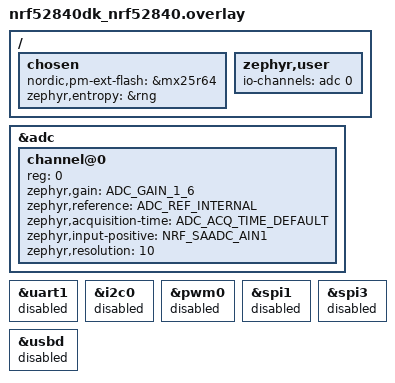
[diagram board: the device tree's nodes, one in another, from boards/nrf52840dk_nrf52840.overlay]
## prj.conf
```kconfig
#
# Copyright (c) 2021 Nordic Semiconductor ASA
#
# SPDX-License-Identifier: LicenseRef-Nordic-5-Clause
#

# This sample uses Kconfig.defaults to set options common for all
# samples. This file should contain only options specific for this sample
# or overrides of default values.

# Enable CHIP
CONFIG_CHIP=y
CONFIG_CHIP_ENABLE_PAIRING_AUTOSTART=y
CONFIG_CHIP_PROJECT_CONFIG="src/chip_project_config.h"
# 32768 == 0x8000 (example Product ID added temporaly,
# but it must be changed with proper PID from the list:
# https://github.com/project-chip/connectedhomeip/blob/482e6fd03196a6de45465a90003947ef4b86e0b1/docs/examples/discussion/PID_allocation_for_example_apps.md)
CONFIG_CHIP_DEVICE_PRODUCT_ID=32768
CONFIG_STD_CPP14=y

# Add support for LEDs and buttons on Nordic development kits
CONFIG_DK_LIBRARY=y

# Bluetooth Low Energy configuration
CONFIG_BT_DEVICE_NAME="MatterTemplate"

# Other settings
CONFIG_THREAD_NAME=y
CONFIG_MPU_STACK_GUARD=y
CONFIG_RESET_ON_FATAL_ERROR=n
CONFIG_CHIP_LIB_SHELL=y

# Disable NFC commissioning
CONFIG_CHIP_NFC_COMMISSIONING=n

# Reduce application size
CONFIG_USE_SEGGER_RTT=n

CONFIG_ADC=y
```

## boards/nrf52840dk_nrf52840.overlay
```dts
/* Copyright (c) 2021 Nordic Semiconductor ASA
 *
 * SPDX-License-Identifier: LicenseRef-Nordic-5-Clause
 */

/ {
	chosen {
		nordic,pm-ext-flash = &mx25r64;
	};
};


/ {
	/*
	* In some default configurations within the nRF Connect SDK,
	* e.g. on nRF52840, the chosen zephyr,entropy node is &cryptocell.
	* This devicetree overlay ensures that default is overridden wherever it
	* is set, as this application uses the RNG node for entropy exclusively.
	*/
	chosen {
		zephyr,entropy = &rng;
	};
};

/ {
	zephyr,user {
		io-channels = <&adc 0>;
	};
};

&adc {
	#address-cells = <1>;
	#size-cells = <0>;

	channel@0 {
		reg = <0>;
		zephyr,gain = "ADC_GAIN_1_6";
		zephyr,reference = "ADC_REF_INTERNAL";
		zephyr,acquisition-time = <ADC_ACQ_TIME_DEFAULT>;
		zephyr,input-positive = <NRF_SAADC_AIN1>; /* P0.03 */
		zephyr,resolution = <10>;
	};
};

/* Disable unused peripherals to reduce power consumption */
&uart1 {
	status = "disabled";
};
&i2c0 {
	status = "disabled";
};
&pwm0 {
	status = "disabled";
};
&spi1 {
	status = "disabled";
};
&spi3 {
	status = "disabled";
};
&usbd {
	status = "disabled";
};
```

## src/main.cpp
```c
/*
 * Copyright (c) 2021 Nordic Semiconductor ASA
 *
 * SPDX-License-Identifier: LicenseRef-Nordic-5-Clause
 */

#include "app_task.h"

#include <zephyr/logging/log.h>

#include <inttypes.h>
#include <stddef.h>
#include <stdint.h>

#include <zephyr/device.h>
#include <zephyr/devicetree.h>
#include <zephyr/drivers/adc.h>
#include <zephyr/kernel.h>
#include <zephyr/sys/printk.h>
#include <zephyr/sys/util.h>

LOG_MODULE_REGISTER(app, CONFIG_CHIP_APP_LOG_LEVEL);

int main()
{
	// int err2;
	// uint32_t count = 0;
	// uint16_t buf;
	// struct adc_sequence sequence = {
	// 	.buffer = &buf,
	// 	/* buffer size in bytes, not number of samples */
	// 	.buffer_size = sizeof(buf),
	// };

	// /* Configure channels individually prior to sampling. */
	// for (size_t i = 0U; i < ARRAY_SIZE(adc_channels); i++) {
	// 	if (!device_is_ready(adc_channels[i].dev)) {
	// 		printk("ADC controller device %s not ready\n", adc_channels[i].dev->name);
	// 		return 0;
	// 	}

	// 	err2 = adc_channel_setup_dt(&adc_channels[i]);
	// 	if (err2 < 0) {
	// 		printk("Could not setup channel #%d (%d)\n", i, err2);
	// 		return 0;
	// 	}
	// }

	// while (1) {
	// 	printk("ADC reading[%u]:\n", count++);
	// 	for (size_t i = 0U; i < ARRAY_SIZE(adc_channels); i++) {
	// 		int32_t val_mv;

	// 		printk("- %s, channel %d: ",
	// 		       adc_channels[i].dev->name,
	// 		       adc_channels[i].channel_id);

	// 		(void)adc_sequence_init_dt(&adc_channels[i], &sequence);

	// 		err2 = adc_read(adc_channels[i].dev, &sequence);
	// 		if (err2 < 0) {
	// 			printk("Could not read (%d)\n", err2);
	// 			continue;
	// 		}

	// 		/*
	// 		 * If using differential mode, the 16 bit value
	// 		 * in the ADC sample buffer should be a signed 2's
	// 		 * complement value.
	// 		 */
	// 		if (adc_channels[i].channel_cfg.differential) {
	// 			val_mv = (int32_t)((int16_t)buf);
	// 		} else {
	// 			val_mv = (int32_t)buf;
	// 		}
	// 		printk("%"PRId32, val_mv);
	// 		err2 = adc_raw_to_millivolts_dt(&adc_channels[i],
	// 					       &val_mv);
	// 		/* conversion to mV may not be supported, skip if not */
	// 		if (err2 < 0) {
	// 			printk(" (value in mV not available)\n");
	// 		} else {
	// 			printk(" = %"PRId32" mV\n", val_mv);
	// 		}
	// 	}

	// 	k_sleep(K_MSEC(1000));
	// }

	CHIP_ERROR err = AppTask::Instance().StartApp();

	LOG_ERR("Exited with code %" CHIP_ERROR_FORMAT, err.Format());
	return err == CHIP_NO_ERROR ? EXIT_SUCCESS : EXIT_FAILURE;
}
```

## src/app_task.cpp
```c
/*
 * Copyright (c) 2021 Nordic Semiconductor ASA
 *
 * SPDX-License-Identifier: LicenseRef-Nordic-5-Clause
 */

#include "app_task.h"
#include "app_config.h"
#include "led_util.h"

#include <platform/CHIPDeviceLayer.h>

#include "board_util.h"
#include <app/server/OnboardingCodesUtil.h>
#include <app/server/Server.h>
#include <credentials/DeviceAttestationCredsProvider.h>
#include <credentials/examples/DeviceAttestationCredsExample.h>
#include <lib/support/CHIPMem.h>
#include <lib/support/CodeUtils.h>
#include <system/SystemError.h>

#ifdef CONFIG_CHIP_WIFI
#include <app/clusters/network-commissioning/network-commissioning.h>
#include <platform/nrfconnect/wifi/NrfWiFiDriver.h>
#endif

#ifdef CONFIG_CHIP_OTA_REQUESTOR
#include "ota_util.h"
#endif

#include <dk_buttons_and_leds.h>
#include <zephyr/kernel.h>
#include <zephyr/logging/log.h>

#include <app-common/zap-generated/attributes/Accessors.h>

#include <zephyr/device.h>
#include <zephyr/devicetree.h>
#include <zephyr/drivers/adc.h>
#include <zephyr/kernel.h>
#include <zephyr/sys/printk.h>
#include <zephyr/sys/util.h>

LOG_MODULE_DECLARE(app, CONFIG_CHIP_APP_LOG_LEVEL);

using namespace ::chip;
using namespace ::chip::app;
using namespace ::chip::Credentials;
using namespace ::chip::DeviceLayer;

namespace
{
constexpr size_t kAppEventQueueSize = 10;
constexpr uint32_t kFactoryResetTriggerTimeout = 6000;

K_MSGQ_DEFINE(sAppEventQueue, sizeof(AppEvent), kAppEventQueueSize, alignof(AppEvent));
k_timer sFunctionTimer;

LEDWidget sStatusLED;
#if NUMBER_OF_LEDS == 2
FactoryResetLEDsWrapper<1> sFactoryResetLEDs{ { FACTORY_RESET_SIGNAL_LED } };
#else
FactoryResetLEDsWrapper<3> sFactoryResetLEDs{ { FACTORY_RESET_SIGNAL_LED, FACTORY_RESET_SIGNAL_LED1,
						FACTORY_RESET_SIGNAL_LED2 } };
#endif

bool sIsNetworkProvisioned = false;
bool sIsNetworkEnabled = false;
bool sHaveBLEConnections = false;
} /* namespace */

namespace LedConsts
{
namespace StatusLed
{
	namespace Unprovisioned
	{
		constexpr uint32_t kOn_ms{ 100 };
		constexpr uint32_t kOff_ms{ kOn_ms };
	} /* namespace Unprovisioned */
	namespace Provisioned
	{
		constexpr uint32_t kOn_ms{ 50 };
		constexpr uint32_t kOff_ms{ 950 };
	} /* namespace Provisioned */

} /* namespace StatusLed */
} /* namespace LedConsts */

#ifdef CONFIG_CHIP_WIFI
app::Clusters::NetworkCommissioning::Instance
	sWiFiCommissioningInstance(0, &(NetworkCommissioning::NrfWiFiDriver::Instance()));
#endif

constexpr size_t kMeasurementsIntervalMs = 3000;

k_timer sSensorTimer;

#if !DT_NODE_EXISTS(DT_PATH(zephyr_user)) || \
	!DT_NODE_HAS_PROP(DT_PATH(zephyr_user), io_channels)
#error "No suitable devicetree overlay specified"
#endif

#define DT_SPEC_AND_COMMA(node_id, prop, idx) \
	ADC_DT_SPEC_GET_BY_IDX(node_id, idx),

/* Data of ADC io-channels specified in devicetree. */
static const struct adc_dt_spec adc_channels[] = {
	DT_FOREACH_PROP_ELEM(DT_PATH(zephyr_user), io_channels,
			     DT_SPEC_AND_COMMA)
};

void SensorTimerHandler(k_timer *timer)
{
	AppEvent event;
	event.Type = AppEventType::SensorMeasure;
	event.Handler = AppTask::SensorMeasureHandler;
	AppTask::Instance().PostEvent(event);
}

CHIP_ERROR AppTask::Init()
{
	/* Initialize CHIP stack */
	LOG_INF("Init CHIP stack");

	CHIP_ERROR err = chip::Platform::MemoryInit();
	if (err != CHIP_NO_ERROR) {
		LOG_ERR("Platform::MemoryInit() failed");
		return err;
	}

	err = PlatformMgr().InitChipStack();
	if (err != CHIP_NO_ERROR) {
		LOG_ERR("PlatformMgr().InitChipStack() failed");
		return err;
	}

#if defined(CONFIG_NET_L2_OPENTHREAD)
	err = ThreadStackMgr().InitThreadStack();
	if (err != CHIP_NO_ERROR) {
		LOG_ERR("ThreadStackMgr().InitThreadStack() failed: %s", ErrorStr(err));
		return err;
	}

#ifdef CONFIG_OPENTHREAD_MTD_SED
	err = ConnectivityMgr().SetThreadDeviceType(ConnectivityManager::kThreadDeviceType_SleepyEndDevice);
#elif CONFIG_OPENTHREAD_MTD
	err = ConnectivityMgr().SetThreadDeviceType(ConnectivityManager::kThreadDeviceType_MinimalEndDevice);
#else
	err = ConnectivityMgr().SetThreadDeviceType(ConnectivityManager::kThreadDeviceType_Router);
#endif /* CONFIG_OPENTHREAD_MTD_SED */
	if (err != CHIP_NO_ERROR) {
		LOG_ERR("ConnectivityMgr().SetThreadDeviceType() failed: %s", ErrorStr(err));
		return err;
	}

#elif defined(CONFIG_CHIP_WIFI)
	sWiFiCommissioningInstance.Init();
#else
	return CHIP_ERROR_INTERNAL;
#endif /* CONFIG_NET_L2_OPENTHREAD */

	/* Initialize LEDs */
	LEDWidget::InitGpio();
	LEDWidget::SetStateUpdateCallback(LEDStateUpdateHandler);

	sStatusLED.Init(SYSTEM_STATE_LED);

	UpdateStatusLED();

	/* Initialize buttons */
	int ret = dk_buttons_init(ButtonEventHandler);
	if (ret) {
		LOG_ERR("dk_buttons_init() failed");
		return chip::System::MapErrorZephyr(ret);
	}

	/* Initialize function timer */
	k_timer_init(&sFunctionTimer, &AppTask::FunctionTimerTimeoutCallback, nullptr);
	k_timer_user_data_set(&sFunctionTimer, this);

	/* Initialize CHIP server */
#if CONFIG_CHIP_FACTORY_DATA
	ReturnErrorOnFailure(mFactoryDataProvider.Init());
	SetDeviceInstanceInfoProvider(&mFactoryDataProvider);
	SetDeviceAttestationCredentialsProvider(&mFactoryDataProvider);
	SetCommissionableDataProvider(&mFactoryDataProvider);
#else
	SetDeviceInstanceInfoProvider(&DeviceInstanceInfoProviderMgrImpl());
	SetDeviceAttestationCredentialsProvider(Examples::GetExampleDACProvider());
#endif

	static chip::CommonCaseDeviceServerInitParams initParams;
	(void)initParams.InitializeStaticResourcesBeforeServerInit();

	ReturnErrorOnFailure(chip::Server::GetInstance().Init(initParams));
	ConfigurationMgr().LogDeviceConfig();
	PrintOnboardingCodes(chip::RendezvousInformationFlags(chip::RendezvousInformationFlag::kBLE));

	/*
	 * Add CHIP event handler and start CHIP thread.
	 * Note that all the initialization code should happen prior to this point to avoid data races
	 * between the main and the CHIP threads.
	 */
	PlatformMgr().AddEventHandler(ChipEventHandler, 0);

	err = PlatformMgr().StartEventLoopTask();
	if (err != CHIP_NO_ERROR) {
		LOG_ERR("PlatformMgr().StartEventLoopTask() failed");
		return err;
	}

	/* Initialize sensor timers*/
	k_timer_init(&sSensorTimer, &SensorTimerHandler, nullptr);
	k_timer_user_data_set(&sSensorTimer, this);
	k_timer_start(&sSensorTimer, K_MSEC(kMeasurementsIntervalMs), K_MSEC(kMeasurementsIntervalMs));

	/* Initialize ADC */
	/* Configure channels individually prior to sampling. */
	for (size_t i = 0U; i < ARRAY_SIZE(adc_channels); i++) {
			if (!device_is_ready(adc_channels[i].dev)) {
				printk("ADC controller device %s not ready\n", adc_channels[i].dev->name);
		 		return chip::System::MapErrorZephyr(-ENODEV);
		 	}

 		int err = adc_channel_setup_dt(&adc_channels[i]);
 		if (err < 0) {
 			printk("Could not setup channel #%d (%d)\n", i, err);
 			return chip::System::MapErrorZephyr(-ENODEV);
 		}
	}

	return CHIP_NO_ERROR;
}

CHIP_ERROR AppTask::StartApp()
{
	ReturnErrorOnFailure(Init());

	AppEvent event = {};

	while (true) {
		k_msgq_get(&sAppEventQueue, &event, K_FOREVER);
		DispatchEvent(event);
	}

	return CHIP_NO_ERROR;
}

void AppTask::ButtonEventHandler(uint32_t buttonState, uint32_t hasChanged)
{
	AppEvent button_event;
	button_event.Type = AppEventType::Button;

	if (FUNCTION_BUTTON_MASK & hasChanged) {
		button_event.ButtonEvent.PinNo = FUNCTION_BUTTON;
		button_event.ButtonEvent.Action =
			static_cast<uint8_t>((FUNCTION_BUTTON_MASK & buttonState) ? AppEventType::ButtonPushed :
										    AppEventType::ButtonReleased);
		button_event.Handler = FunctionHandler;
		PostEvent(button_event);
	}
}

void AppTask::FunctionTimerTimeoutCallback(k_timer *timer)
{
	if (!timer) {
		return;
	}

	AppEvent event;
	event.Type = AppEventType::Timer;
	event.TimerEvent.Context = k_timer_user_data_get(timer);
	event.Handler = FunctionTimerEventHandler;
	PostEvent(event);
}

void AppTask::FunctionTimerEventHandler(const AppEvent &)
{
	if (Instance().mFunction == FunctionEvent::FactoryReset) {
		Instance().mFunction = FunctionEvent::NoneSelected;
		LOG_INF("Factory Reset triggered");

		sStatusLED.Set(true);
		sFactoryResetLEDs.Set(true);

		chip::Server::GetInstance().ScheduleFactoryReset();
	}
}

void AppTask::FunctionHandler(const AppEvent &event)
{
	if (event.ButtonEvent.PinNo != FUNCTION_BUTTON)
		return;

	if (event.ButtonEvent.Action == static_cast<uint8_t>(AppEventType::ButtonPushed)) {
		Instance().StartTimer(kFactoryResetTriggerTimeout);
		Instance().mFunction = FunctionEvent::FactoryReset;
	} else if (event.ButtonEvent.Action == static_cast<uint8_t>(AppEventType::ButtonReleased)) {
		if (Instance().mFunction == FunctionEvent::FactoryReset) {
			sFactoryResetLEDs.Set(false);
			UpdateStatusLED();
			Instance().CancelTimer();
			Instance().mFunction = FunctionEvent::NoneSelected;
			LOG_INF("Factory Reset has been Canceled");
		}
	}
}

void AppTask::LEDStateUpdateHandler(LEDWidget &ledWidget)
{
	AppEvent event;
	event.Type = AppEventType::UpdateLedState;
	event.Handler = UpdateLedStateEventHandler;
	event.UpdateLedStateEvent.LedWidget = &ledWidget;
	PostEvent(event);
}

void AppTask::UpdateLedStateEventHandler(const AppEvent &event)
{
	if (event.Type == AppEventType::UpdateLedState) {
		event.UpdateLedStateEvent.LedWidget->UpdateState();
	}
}

void AppTask::UpdateStatusLED()
{
	/* Update the status LED.
	 *
	 * If IPv6 networking and service provisioned, keep the LED On constantly.
	 *
	 * If the system has BLE connection(s) uptill the stage above, THEN blink the LED at an even
	 * rate of 100ms.
	 *
	 * Otherwise, blink the LED for a very short time. */
	if (sIsNetworkProvisioned && sIsNetworkEnabled) {
		sStatusLED.Set(true);
	} else if (sHaveBLEConnections) {
		sStatusLED.Blink(LedConsts::StatusLed::Unprovisioned::kOn_ms,
				 LedConsts::StatusLed::Unprovisioned::kOff_ms);
	} else {
		sStatusLED.Blink(LedConsts::StatusLed::Provisioned::kOn_ms, LedConsts::StatusLed::Provisioned::kOff_ms);
	}
}

void AppTask::ChipEventHandler(const ChipDeviceEvent *event, intptr_t /* arg */)
{
	switch (event->Type) {
	case DeviceEventType::kCHIPoBLEAdvertisingChange:
		sHaveBLEConnections = ConnectivityMgr().NumBLEConnections() != 0;
		UpdateStatusLED();
		break;
#if defined(CONFIG_NET_L2_OPENTHREAD)
	case DeviceEventType::kDnssdInitialized:
#if CONFIG_CHIP_OTA_REQUESTOR
		InitBasicOTARequestor();
#endif /* CONFIG_CHIP_OTA_REQUESTOR */
		break;
	case DeviceEventType::kThreadStateChange:
		sIsNetworkProvisioned = ConnectivityMgr().IsThreadProvisioned();
		sIsNetworkEnabled = ConnectivityMgr().IsThreadEnabled();
#elif defined(CONFIG_CHIP_WIFI)
	case DeviceEventType::kWiFiConnectivityChange:
		sIsNetworkProvisioned = ConnectivityMgr().IsWiFiStationProvisioned();
		sIsNetworkEnabled = ConnectivityMgr().IsWiFiStationEnabled();
#if CONFIG_CHIP_OTA_REQUESTOR
		if (event->WiFiConnectivityChange.Result == kConnectivity_Established) {
			InitBasicOTARequestor();
		}
#endif /* CONFIG_CHIP_OTA_REQUESTOR */
#endif
		UpdateStatusLED();
		break;
	default:
		break;
	}
}

void AppTask::CancelTimer()
{
	k_timer_stop(&sFunctionTimer);
}

void AppTask::StartTimer(uint32_t timeoutInMs)
{
	k_timer_start(&sFunctionTimer, K_MSEC(timeoutInMs), K_NO_WAIT);
}

void AppTask::PostEvent(const AppEvent &event)
{
	if (k_msgq_put(&sAppEventQueue, &event, K_NO_WAIT) != 0) {
		LOG_INF("Failed to post event to app task event queue");
	}
}

void AppTask::DispatchEvent(const AppEvent &event)
{
	if (event.Handler) {
		event.Handler(event);
	} else {
		LOG_INF("Event received with no handler. Dropping event.");
	}
}

void AppTask::SensorMeasureHandler(const AppEvent &)
{
	uint16_t buf;
	struct adc_sequence sequence = {
		.buffer = &buf,
		/* buffer size in bytes, not number of samples */
		.buffer_size = sizeof(buf),
	};

	int16_t val_mv;
	printk("ADC reading\n");
 	for (size_t i = 0U; i < ARRAY_SIZE(adc_channels); i++) {

 		printk("- %s, channel %d: ",
 		       adc_channels[i].dev->name,
		       adc_channels[i].channel_id);

 		(void)adc_sequence_init_dt(&adc_channels[i], &sequence);

 		int err = adc_read(adc_channels[i].dev, &sequence);
 		if (err < 0) {
 			printk("Could not read (%d)\n", err);
 			continue;
 		}

		uint16_t buf2 = buf;
		printk("%" PRId32, buf2);
		printk(" - ");
		val_mv = (250 * (920 - buf2)) / 7;
		printk("%" PRId32, val_mv);
	}

	EmberAfStatus status;
	status = chip::app::Clusters::RelativeHumidityMeasurement::Attributes::MeasuredValue::Set(1, val_mv);
	if (status == EMBER_ZCL_STATUS_SUCCESS) {
		LOG_INF("Wrote new value");
	} else {
		LOG_ERR("Updating temperature measurement %x", status);
	}
}
```

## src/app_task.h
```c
/*
 * Copyright (c) 2021 Nordic Semiconductor ASA
 *
 * SPDX-License-Identifier: LicenseRef-Nordic-5-Clause
 */

#pragma once

#include "app_event.h"
#include "led_widget.h"

#include <platform/CHIPDeviceLayer.h>

#if CONFIG_CHIP_FACTORY_DATA
#include <platform/nrfconnect/FactoryDataProvider.h>
#else
#include <platform/nrfconnect/DeviceInstanceInfoProviderImpl.h>
#endif

struct k_timer;

class AppTask {
public:
	static AppTask &Instance()
	{
		static AppTask sAppTask;
		return sAppTask;
	};

	CHIP_ERROR StartApp();

	static void PostEvent(const AppEvent &event);
	static void SensorMeasureHandler(const AppEvent &event);

private:
	CHIP_ERROR Init();

	void CancelTimer();
	void StartTimer(uint32_t timeoutInMs);

	static void DispatchEvent(const AppEvent &event);
	static void UpdateLedStateEventHandler(const AppEvent &event);
	static void FunctionHandler(const AppEvent &event);
	static void FunctionTimerEventHandler(const AppEvent &event);

	static void ChipEventHandler(const chip::DeviceLayer::ChipDeviceEvent *event, intptr_t arg);
	static void ButtonEventHandler(uint32_t buttonState, uint32_t hasChanged);
	static void LEDStateUpdateHandler(LEDWidget &ledWidget);
	static void FunctionTimerTimeoutCallback(k_timer *timer);
	static void UpdateStatusLED();

	FunctionEvent mFunction = FunctionEvent::NoneSelected;
	bool mFunctionTimerActive = false;

#if CONFIG_CHIP_FACTORY_DATA
	chip::DeviceLayer::FactoryDataProvider<chip::DeviceLayer::InternalFlashFactoryData> mFactoryDataProvider;
#endif
};
```
